NS_ :

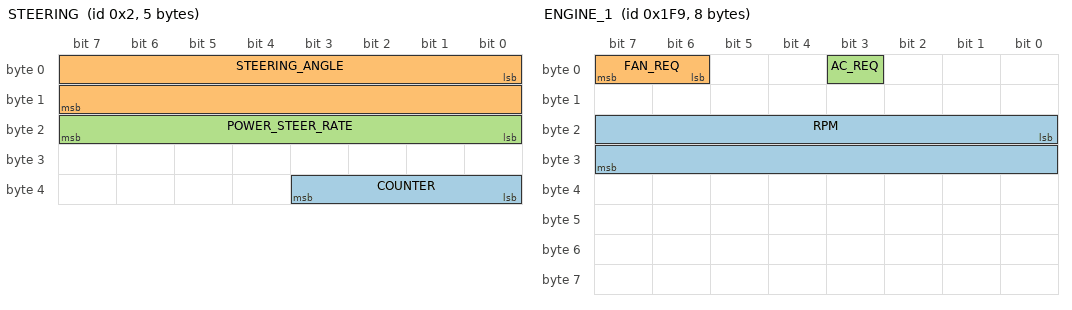
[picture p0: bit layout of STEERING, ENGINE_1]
BO_ 2 STEERING: 5 XXX
 SG_ COUNTER : 35|4@0+ (1,0) [0|255] "" XXX
 SG_ STEERING_ANGLE : 0|16@1- (0.1,0) [0|65535] "deg" XXX
 SG_ POWER_STEER_RATE : 23|8@0+ (1,0) [0|255] "" XXX

BO_ 505 ENGINE_1: 8 XXX
 SG_ RPM : 16|16@1+ (0.125,0) [0|45000] "R/min" XXX
 SG_ FAN_REQ : 6|2@1+ (1,0) [0|3] "" XXX
 SG_ AC_REQ : 3|1@1+ (1,0) [0|1] "" XXX

BO_ 561 ENGINE_2: 8 XXX
 SG_ Pedal_position : 16|8@1+ (0.5,0) [0|200] "%" XXX

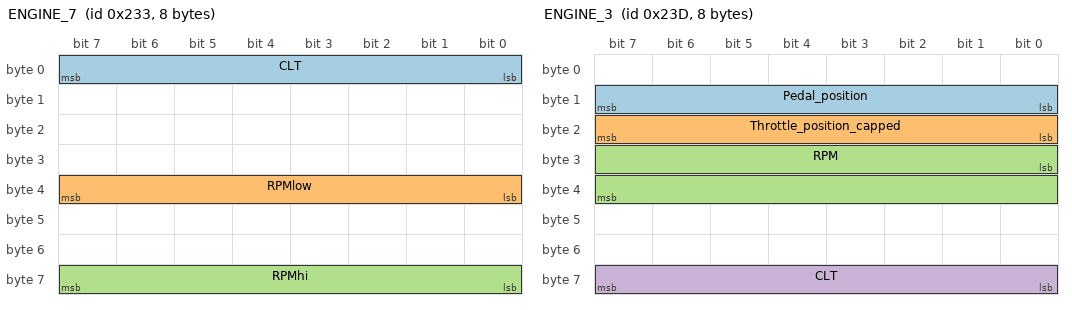
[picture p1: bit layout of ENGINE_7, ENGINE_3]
BO_ 563 ENGINE_7: 8 XXX
 SG_ CLT : 0|8@1+ (0.366666,0) [0|255] "C" XXX
 SG_ RPMlow : 32|8@1+ (3.15,0) [0|45000] "R/min" XXX
 SG_ RPMhi : 56|8@1+ (3.15,0) [0|45000] "R/min" XXX

BO_ 573 ENGINE_3: 8 XXX
 SG_ Pedal_position : 8|8@1+ (0.392,0) [0|255] "%" XXX
 SG_ Throttle_position_capped : 16|8@1+ (0.392,0) [0|255] "%" XXX
 SG_ RPM : 24|16@1+ (3.15,0) [0|45000] "R/min" XXX
 SG_ CLT : 56|8@1+ (0.366666,0) [0|255] "C" XXX

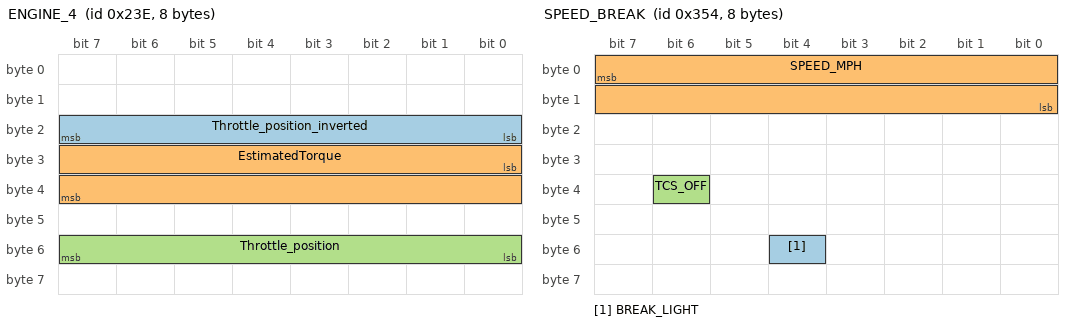
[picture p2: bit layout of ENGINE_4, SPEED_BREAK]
BO_ 574 ENGINE_4: 8 XXX
 SG_ Throttle_position_inverted : 16|8@1+ (0.392,0) [0|255] "%" XXX
 SG_ EstimatedTorque : 24|16@1+ (0.1,0) [0|45000] "nM" XXX
 SG_ Throttle_position : 48|8@1+ (0.392,0) [0|255] "%" XXX

BO_ 595 TCU_1: 8 XXX
 SG_ SHAFT_1_SPEED : 32|16@1+ (1,0) [0|45000] "r/min" XXX
 SG_ SHAFT_2_SPEED : 48|16@1+ (1,0) [0|45000] "r/min" XXX

BO_ 640 SPEED: 8 XXX
 SG_ SPEED : 32|16@1+ (0.01,0) [0|45000] "km/h" XXX

BO_ 644 ABS_1: 8 XXX
 SG_ WHEEL_1 : 0|16@1+ (0.01,0) [0|45000] "km/h" XXX
 SG_ WHEEL_2 : 15|16@1+ (0.01,0) [0|45000] "km/h" XXX

BO_ 645 ABS_2: 8 XXX
 SG_ WHEEL_3 : 0|16@1+ (0.01,0) [0|45000] "km/h" XXX
 SG_ WHEEL_4 : 15|16@1+ (0.01,0) [0|45000] "km/h" XXX

BO_ 852 SPEED_BREAK: 8 XXX
 SG_ BREAK_LIGHT : 52|1@0+ (1,0) [0|3] "" XXX
 SG_ SPEED_MPH : 7|16@0+ (0.0066,0) [0|65535] "mph" XXX
 SG_ TCS_OFF : 38|1@0+ (1,0) [0|255] "" XXX

BO_ 861 BCM: 8 XXX

BO_ 1361 ENGINE_5: 8 XXX
 SG_ CLT : 0|8@1+ (1,-45) [-45|150] "" XXX

BO_ 1408 ENGINE_6: 8 XXX
 SG_ RPM : 7|16@0+ (1.5,0) [0|65535] "" XXX
 SG_ OIL_TEMP : 32|8@1+ (1,-40) [-40|150] "" XXX

BU_: K16_BECM K73_TCIC K9_BCM K43_PSCM K17_EBCM K20_ECM K114B_HPCM NEO K124_ASCM EPB
VAL_TABLE_ TurnSignals 2 "Right Turn" 1 "Left Turn" 0 "None" ;
VAL_TABLE_ Intellibeam 1 "Active" 0 "Inactive" ;
VAL_TABLE_ HighBeamsActive 1 "Active" 0 "Inactive" ;
VAL_TABLE_ HighBeamsTemporary 1 "Active" 0 "Inactive" ;
VAL_TABLE_ ACCLeadCar 1 "Present" 0 "Not Present" ;
VAL_TABLE_ ACCCmdActive 1 "Active" 0 "Inactive" ;
VAL_TABLE_ BrakePedalPressed 1 "Pressed" 0 "Depressed" ;
VAL_TABLE_ DistanceButton 1 "Active" 0 "Inactive" ;
VAL_TABLE_ LKAButton 1 "Active" 0 "Inactive" ;
VAL_TABLE_ ACCButtons 6 "Cancel" 5 "Main" 3 "Set" 2 "Resume" 1 "None" ;
VAL_TABLE_ DriveModeButton 1 "Active" 0 "Inactive" ;
VAL_TABLE_ PRNDL 3 "Reverse" 2 "Drive" 1 "Neutral" 0 "Park" ;
VAL_TABLE_ ESPButton 1 "Active" 0 "Inactive" ;
VAL_TABLE_ DoorStatus 1 "Opened" 0 "Closed" ;
VAL_TABLE_ SeatBeltStatus 1 "Latched" 0 "Unlatched" ;
VAL_TABLE_ LKASteeringCmdActive 1 "Active" 0 "Inactive" ;
VAL_TABLE_ ACCGapLevel 3 "Far" 2 "Med" 1 "Near" 0 "Inactive" ;
VAL_TABLE_ GasRegenCmdActiveInv 1 "Inactive" 0 "Active" ;
VAL_TABLE_ GasRegenCmdActive 1 "Active" 0 "Inactive" ;
VAL_TABLE_ LKATorqueDeliveredStatus 3 "Failed" 2 "Temp. Limited" 1 "Active" 0 "Inactive" ;
VAL_TABLE_ HandsOffSWDetectionStatus 1 "Hands On" 0 "Hands Off" ;
VAL_TABLE_ HandsOffSWDetectionMode 2 "Failed" 1 "Enabled" 0 "Disabled" ;

VAL_ 368 Gear_State 4 "D" 2 "N" 1 "R" 0 "P" ;
